# STM32WL55xx register map
File version: 1.0
Registers are 32-bit, read-write, reset 0x0 unless marked. A register's access mark holds for its fields unless they carry their own. Offsets are from the block's base; [hi:lo] are bit positions; {n}, {i} and the like mark numbered series.

## SYSCFG — System configuration controller
Base 0x40010000
0x00 MEMRMP — SYSCFG memory remap register
  [2:0] MEM_MODE — SYSCFG_Memory Remap Config
    0=FLASH (Main Flash memory mapped at 0x00000000); 1=SYSTEMFLASH (System Flash memory mapped at 0x00000000); 3=SRAM (SRAM1 mapped at 0x00000000)
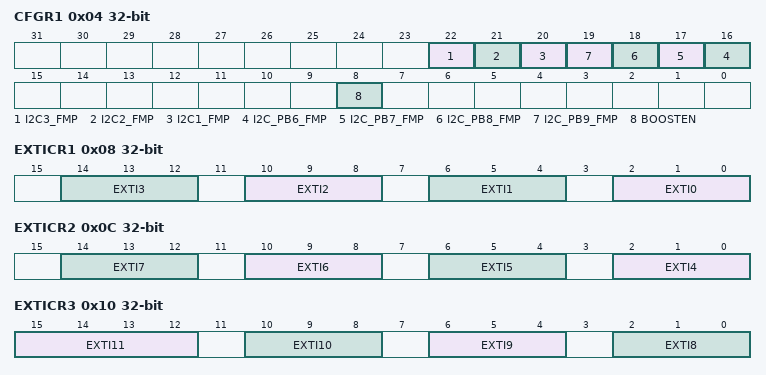
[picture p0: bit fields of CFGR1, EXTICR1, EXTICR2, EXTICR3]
0x04 CFGR1 — SYSCFG configuration register 1
  [22] I2C3_FMP — I2C3 Fast-mode Plus (Fm+) driving capability activation
  [21] I2C2_FMP — I2C2 Fast-mode Plus (Fm+) driving capability activation
  [20] I2C1_FMP — I2C1 Fast-mode Plus (Fm+) driving capability activation
  [n+10] I2C_PB{n}_FMP (n=6..9) — Fast-mode Plus (Fm+) driving capability activation on PB{n}
  [8] BOOSTEN — I/O analog switch voltage booster enable
0x08 EXTICR1 — SYSCFG external interrupt configuration registers
  [4n+2:4n] EXTI{n} (n=0..3) — External Interrupt Line {n} configuration
0x0C EXTICR2 — SYSCFG external interrupt configuration registers
  [4n-14:4n-16] EXTI{n} (n=4..7) — External Interrupt Line {n} configuration
0x10 EXTICR3 — SYSCFG external interrupt configuration registers
  [15:12] EXTI11 — External Interrupt Line 11 configuration
  [10:8] EXTI10 — External Interrupt Line 10 configuration
  [6:4] EXTI9 — External Interrupt Line 9 configuration
  [2:0] EXTI8 — External Interrupt Line 8 configuration
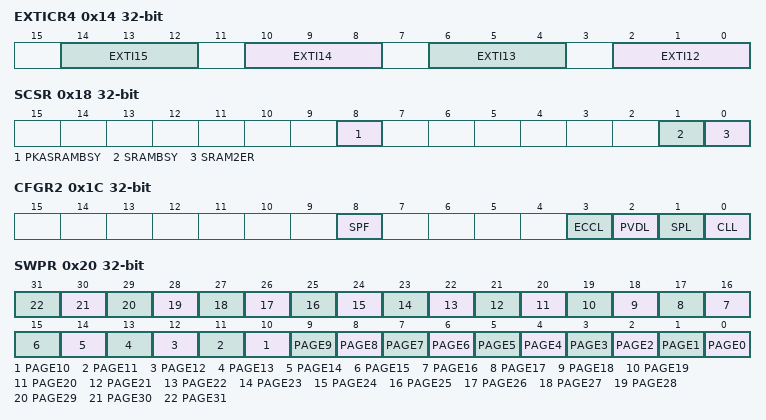
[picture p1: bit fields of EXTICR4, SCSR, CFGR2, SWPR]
0x14 EXTICR4 — SYSCFG external interrupt configuration registers
  [4n-46:4n-48] EXTI{n} (n=12..15) — External Interrupt Line {n} configuration
0x18 SCSR — SYSCFG SRAM2 control and status register
  [8] PKASRAMBSY — PKA SRAM busy by erase operation
  [1] SRAMBSY — SRAM2 and SRAM1 busy by erase operation
  [0] SRAM2ER — SRAM2 Erase
0x1C CFGR2 — SYSCFG configuration register 2
  [8] SPF — SRAM2 Parity Lock
  [3] ECCL — ECC Lock
  [2] PVDL — PVD Lock
  [1] SPL — SRAM2 Parity Lock
  [0] CLL — Cortex M4 LOCKUP (hardfault) output enable
0x20 SWPR — SYSCFG SRAM2 write protection register part
  [n] PAGE{n} (n=0..31) — SRAM2 Write protection page {n} ({0x20008000+0x400*n} - {0x200083FF+0x400*n})
0x24 SKR — SYSCFG SRAM2 key register
  [7:0] KEY — SRAM2 write protection key for software erase
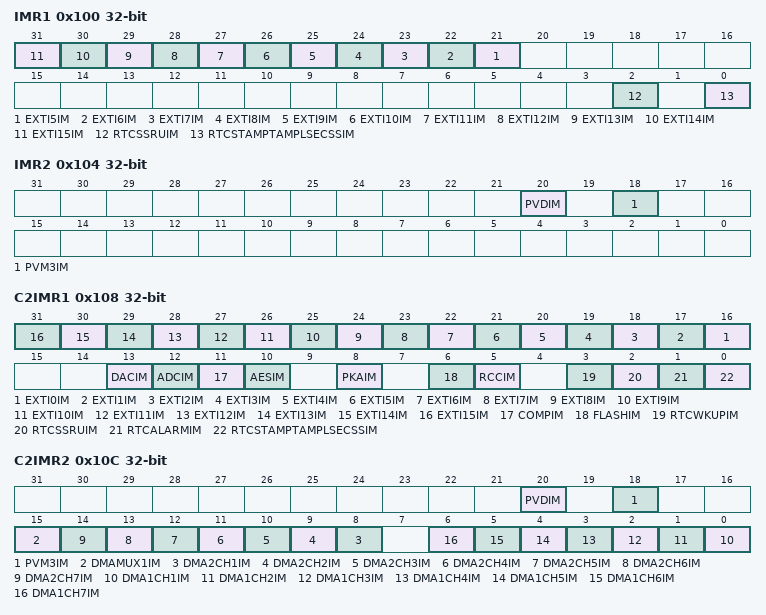
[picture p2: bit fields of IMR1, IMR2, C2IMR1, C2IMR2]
0x100 IMR1 — SYSCFG CPU1 (CORTEX M4) interrupt masks control-status register part 1
  [n+16] EXTI{n}IM (n=5..15) — Enabling of interrupt from External Interrupt Line {n} to CPU1
  [2] RTCSSRUIM — Enabling of interrupt from RTC SSRU to CPU1
  [0] RTCSTAMPTAMPLSECSSIM — Enabling of interrupt from RTCSTAMPTAMPLSECSS to CPU1
0x104 IMR2 — SYSCFG CPU1 (CORTEX M4) interrupt masks control-status register part 2
  [20] PVDIM — Enabling of interrupt from Power Voltage Detector to CPU1
  [18] PVM3IM — Enabling of interrupt from Power Voltage Monitoring 3 to CPU1
0x108 C2IMR1 — SYSCFG CPU2 (CORTEX M0) interrupt masks control-status register part 1
  [n+16] EXTI{n}IM (n=0..15) — Enabling of interrupt from External Interrupt Line {n} to CPU2
  [13] DACIM — Enabling of interrupt from Digital Analog Converter to CPU2
  [12] ADCIM — Enabling of interrupt from Analog Digital Converter to CPU2
  [11] COMPIM — Enabling of interrupt from Comparator to CPU2
  [10] AESIM — Enabling of interrupt from AES to CPU2
  [8] PKAIM — Enabling of interrupt from PKA to CPU2
  [6] FLASHIM — Enabling of interrupt from FLASH to CPU2
  [5] RCCIM — Enabling of interrupt from RCC to CPU2
  [3] RTCWKUPIM — Enabling of interrupt from RTC Wakeup to CPU2
  [2] RTCSSRUIM — Enabling of interrupt from RTC SSRU to CPU2
  [1] RTCALARMIM — Enabling of interrupt from RTC Alarms to CPU2
  [0] RTCSTAMPTAMPLSECSSIM
0x10C C2IMR2 — SYSCFG CPU2 (CORTEX M0) interrupt masks control-status register part 2
  [20] PVDIM — Enabling of interrupt from Power Voltage Detector to CPU2
  [18] PVM3IM — Enabling of interrupt from Power Voltage Monitoring 3 to CPU2
  [15] DMAMUX1IM — Enabling of interrupt from DMAMUX1 to CPU2
  [n+7] DMA2CH{n}IM (n=1..7) — Enabling of interrupt from DMA2 Channel {n} to CPU2
  [n-1] DMA1CH{n}IM (n=1..7) — Enabling of interrupt from DMA1 Channel {n} to CPU2
0x208 RFDCR — SYSCFG CPU2 radio debug control register
  [0] RFTBSEL — Radio debug test bus selection
    1=ANALOG_TEST_BUS (Analog test bus selected on RF_ADTB[3:0]); 0=DIGITAL_TEST_BUS (Digital test bus selected on RF_ADTB[3:0])
